# XMC4400 register map
Vendor: Infineon; File version: 1.5.3 (Reference Manual v1.5)
CPU: CM4 r2p0, little endian, MPU, FPU, 6 interrupt priority bits
Registers are 32-bit, read-write, reset 0x0 unless marked. A register's access mark holds for its fields unless they carry their own. Offsets are from the block's base; [hi:lo] are bit positions; {n}, {i} and the like mark numbered series; 'fields as' and 'values as' point back to an identical list.

## PORT14
Base 0x48028E00
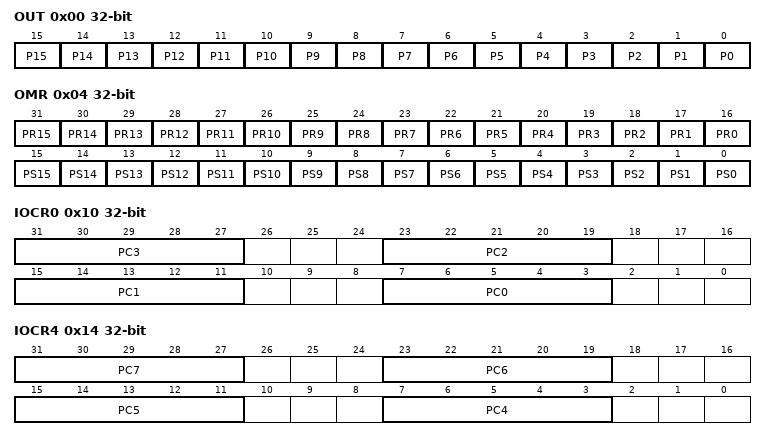
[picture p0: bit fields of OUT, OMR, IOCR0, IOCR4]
0x00 OUT — Port 14 Output Register
  [all] fields
    0=The output level of Pn.x is 0; 1=The output level of Pn.x is 1
  [n] P{n} (n=0..15) — Port n Output Bit {n}
0x04 OMR wo — Port 14 Output Modification Register
  [n+16] PR{n} (n=0..15) — Port n Reset Bit {n}
  [n] PS{n} (n=0..15) — Port n Set Bit {n}
0x10 IOCR0 — Port 14 Input/Output Control Register 0
  [all] fields
    0=Input - No internal pull device active; 1=Input - Internal pull-down device active; 2=Input - Internal pull-up device active; 3=Input - No internal pull device, Pn_OUTx = input value; 4=Input inverted - No internal pull device active; 5=Input inverted - Internal pull-down device active; 6=Input inverted - Internal pull-up device active; 7=Input inverted - No internal pull device, Pn_OUTx = input value; 16=Output Push-Pull - General-purpose output; {v}=Output Push-Pull - Alternate output function {v-16} (v=17..20); 24=Output Open Drain - General-purpose output; {v}=Output Open Drain - Alternate output function {v-24} (v=25..28)
  [8n+7:8n+3] PC{n} (n=0..3) — Port Control for Port n Pin 0 to 3
0x14 IOCR4 — Port 14 Input/Output Control Register 4
  [all] fields
    values as the fields of IOCR0
  [8n-25:8n-29] PC{n} (n=4..7) — Port Control for Port n Pin 4 to 7
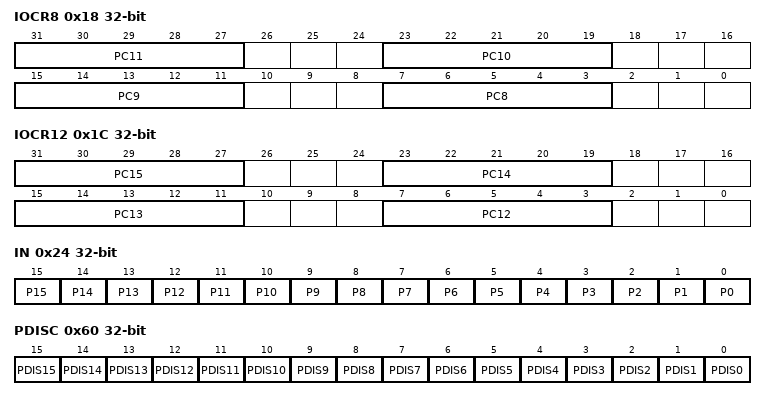
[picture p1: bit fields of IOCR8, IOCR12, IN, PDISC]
0x18 IOCR8 — Port 14 Input/Output Control Register 8
  [all] fields
    values as the fields of IOCR0
  [8n-57:8n-61] PC{n} (n=8..11) — Port Control for Port n Pin 8 to 11
0x1C IOCR12 — Port 14 Input/Output Control Register 12
  [all] fields
    values as the fields of IOCR0
  [8n-89:8n-93] PC{n} (n=12..15) — Port Control for Port n Pin 12 to 15
0x24 IN ro (reset mask 0xFFFF0000) — Port 14 Input Register
  [all] fields
    0=The input level of Pn.x is 0; 1=The input level of Pn.x is 1
  [n] P{n} (n=0..15) — Port n Input Bit {n}
0x60 PDISC (reset mask 0xFFFF0000) — Port 14 Pin Function Decision Control Register
  [all] fields
    0=Digital Pad input is enabled. Analog and digital input path active.; 1=Digital Pad input is disabled. Analog input path active. (default)
  [n] PDIS{n} (n=0..15) — Pad Disable for Port n Pin {n}
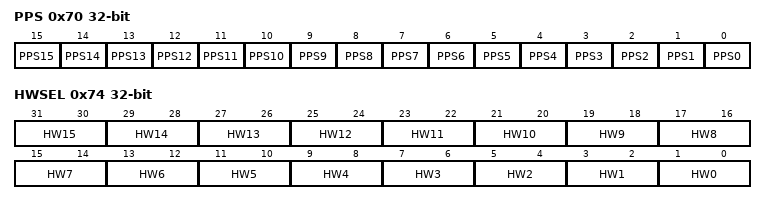
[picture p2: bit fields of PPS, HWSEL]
0x70 PPS — Port 14 Pin Power Save Register
  [all] fields
    0=Pin Power Save of Pn.x is disabled; 1=Pin Power Save of Pn.x is enabled
  [n] PPS{n} (n=0..15) — Port n Pin Power Save Bit {n}
0x74 HWSEL — Port 14 Pin Hardware Select Register
  [all] fields
    0=Software control only; 1=HW0 control path can override the software configuration; 2=HW1 control path can override the software configuration
  [2n+1:2n] HW{n} (n=0..15) — Port n Pin Hardware Select Bit {n}

## PORT15
Base 0x48028F00
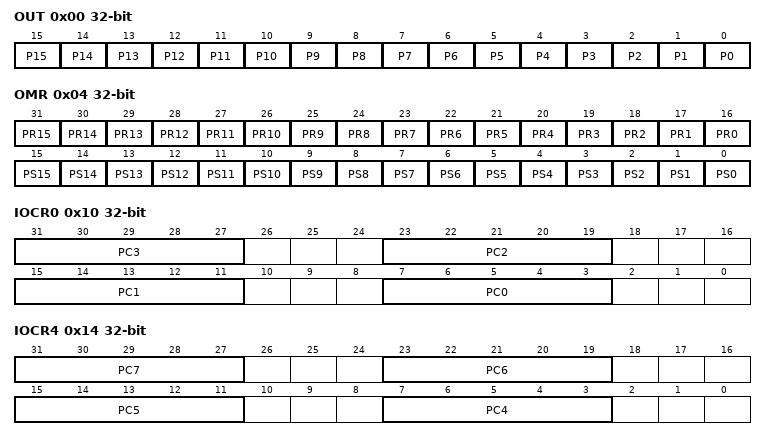
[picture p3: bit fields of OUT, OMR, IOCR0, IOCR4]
0x00 OUT — Port 15 Output Register
  [all] fields
    0=The output level of Pn.x is 0; 1=The output level of Pn.x is 1
  [n] P{n} (n=0..15) — Port n Output Bit {n}
0x04 OMR wo — Port 15 Output Modification Register
  [n+16] PR{n} (n=0..15) — Port n Reset Bit {n}
  [n] PS{n} (n=0..15) — Port n Set Bit {n}
0x10 IOCR0 — Port 15 Input/Output Control Register 0
  [all] fields
    0=Input - No internal pull device active; 1=Input - Internal pull-down device active; 2=Input - Internal pull-up device active; 3=Input - No internal pull device, Pn_OUTx = input value; 4=Input inverted - No internal pull device active; 5=Input inverted - Internal pull-down device active; 6=Input inverted - Internal pull-up device active; 7=Input inverted - No internal pull device, Pn_OUTx = input value; 16=Output Push-Pull - General-purpose output; {v}=Output Push-Pull - Alternate output function {v-16} (v=17..20); 24=Output Open Drain - General-purpose output; {v}=Output Open Drain - Alternate output function {v-24} (v=25..28)
  [8n+7:8n+3] PC{n} (n=0..3) — Port Control for Port n Pin 0 to 3
0x14 IOCR4 — Port 15 Input/Output Control Register 4
  [all] fields
    values as the fields of IOCR0
  [8n-25:8n-29] PC{n} (n=4..7) — Port Control for Port n Pin 4 to 7
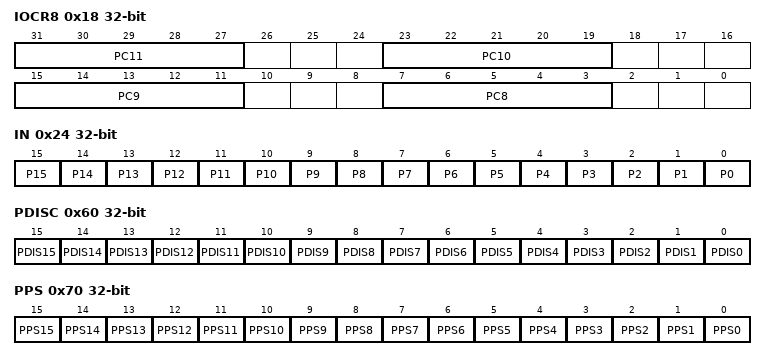
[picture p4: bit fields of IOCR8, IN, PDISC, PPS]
0x18 IOCR8 — Port 15 Input/Output Control Register 8
  [all] fields
    values as the fields of IOCR0
  [8n-57:8n-61] PC{n} (n=8..11) — Port Control for Port n Pin 8 to 11
0x24 IN ro (reset mask 0xFFFF0000) — Port 15 Input Register
  [all] fields
    0=The input level of Pn.x is 0; 1=The input level of Pn.x is 1
  [n] P{n} (n=0..15) — Port n Input Bit {n}
0x60 PDISC (reset mask 0xFFFF0000) — Port 15 Pin Function Decision Control Register
  [all] fields
    0=Digital Pad input is enabled. Analog and digital input path active.; 1=Digital Pad input is disabled. Analog input path active. (default)
  [n] PDIS{n} (n=0..15) — Pad Disable for Port n Pin {n}
0x70 PPS — Port 15 Pin Power Save Register
  [all] fields
    0=Pin Power Save of Pn.x is disabled; 1=Pin Power Save of Pn.x is enabled
  [n] PPS{n} (n=0..15) — Port n Pin Power Save Bit {n}
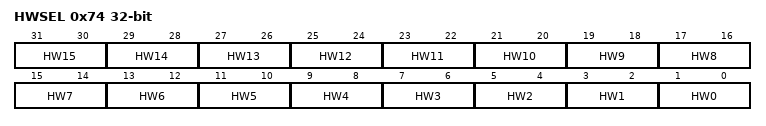
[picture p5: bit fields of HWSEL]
0x74 HWSEL — Port 15 Pin Hardware Select Register
  [all] fields
    0=Software control only; 1=HW0 control path can override the software configuration; 2=HW1 control path can override the software configuration
  [2n+1:2n] HW{n} (n=0..15) — Port n Pin Hardware Select Bit {n}
